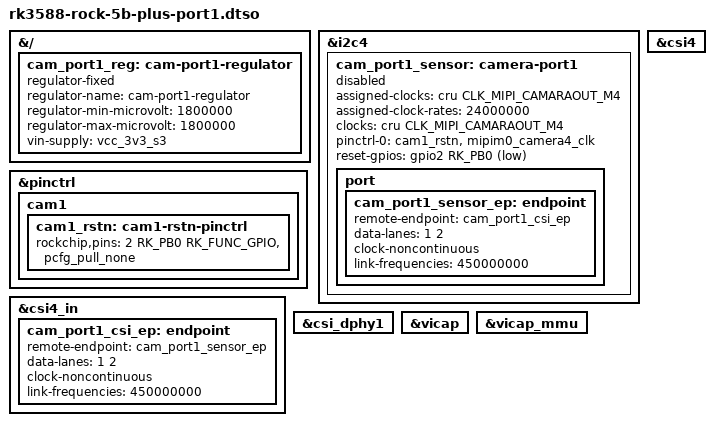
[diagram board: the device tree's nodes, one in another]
// SPDX-License-Identifier: (GPL-2.0+ OR MIT)
/*
 * ROCK 5B+ CAM1 (port1): Inno CSI D-PHY1 + CSI4 on i2c4.
 *
 * Publishes cam_port1_sensor, cam_port1_sensor_ep, cam_port1_csi_ep,
 * and cam_port1_reg. Which ISP is enabled is chosen per camera, not by
 * this port.
 */

/dts-v1/;
/plugin/;

#include <dt-bindings/clock/rockchip,rk3588-cru.h>
#include <dt-bindings/gpio/gpio.h>
#include <dt-bindings/pinctrl/rockchip.h>

&{/} {
	cam_port1_reg: cam-port1-regulator {
		compatible = "regulator-fixed";
		regulator-name = "cam-port1-regulator";
		regulator-min-microvolt = <1800000>;
		regulator-max-microvolt = <1800000>;
		vin-supply = <&vcc_3v3_s3>;
	};
};

&i2c4 {
	#address-cells = <1>;
	#size-cells = <0>;
	status = "okay";

	cam_port1_sensor: camera-port1 {
		status = "disabled";
		assigned-clocks = <&cru CLK_MIPI_CAMARAOUT_M4>;
		assigned-clock-rates = <24000000>;
		clocks = <&cru CLK_MIPI_CAMARAOUT_M4>;
		pinctrl-names = "default";
		pinctrl-0 = <&cam1_rstn &mipim0_camera4_clk>;
		reset-gpios = <&gpio2 RK_PB0 GPIO_ACTIVE_LOW>;

		port {
			cam_port1_sensor_ep: endpoint {
				remote-endpoint = <&cam_port1_csi_ep>;
				data-lanes = <1 2>;
				clock-noncontinuous;
				link-frequencies = /bits/ 64 <450000000>;
			};
		};
	};
};

&pinctrl {
	cam1 {
		cam1_rstn: cam1-rstn-pinctrl {
			rockchip,pins = <2 RK_PB0 RK_FUNC_GPIO &pcfg_pull_none>;
		};
	};
};

&csi4 {
	status = "okay";
};

&csi4_in {
	cam_port1_csi_ep: endpoint {
		remote-endpoint = <&cam_port1_sensor_ep>;
		data-lanes = <1 2>;
		clock-noncontinuous;
		link-frequencies = /bits/ 64 <450000000>;
	};
};

&csi_dphy1 {
	status = "okay";
};

&vicap {
	status = "okay";
};

&vicap_mmu {
	status = "okay";
};
